# nrf54lv10a_enga_application register map
Vendor: Nordic Semiconductor; Series: nrf54l; File version: 1
CPU: CM33 r0p4, little endian, MPU, FPU, 3 interrupt priority bits, 270 interrupts, 4 SAU regions
Registers are 32-bit, read-write, reset 0x0 unless marked. A register's access mark holds for its fields unless they carry their own. Offsets are from the block's base; [hi:lo] are bit positions; lines under a group give offsets from that group; {n}, {i} and the like mark numbered series; 'fields as' and 'values as' point back to an identical list.

## GLOBAL_SAADC_NS — Analog to Digital Converter 0
Base 0x400D5000
Same registers: GLOBAL_SAADC_S 0x500D5000
0x00 TASKS_START wo — Start the ADC and prepare the result buffer in RAM
  [0] TASKS_START
    1=Trigger task
0x04 TASKS_SAMPLE wo — Take one ADC sample, if scan is enabled all channels are sampled. This task requires that SAADC has started, i.e. EVENTS_STARTED was set and EVENTS_STOPPED was not.
  [0] TASKS_SAMPLE
    1=Trigger task
0x08 TASKS_STOP wo — Stop the ADC and terminate any on-going conversion
  [0] TASKS_STOP
    1=Trigger task
0x0C TASKS_CALIBRATEOFFSET wo — Starts offset auto-calibration
  [0] TASKS_CALIBRATEOFFSET
    1=Trigger task
0x18 TASKS_STOPDMA wo — Stops DMA transfer sub module
  [0] TASKS_STOPDMA
    1=Trigger task
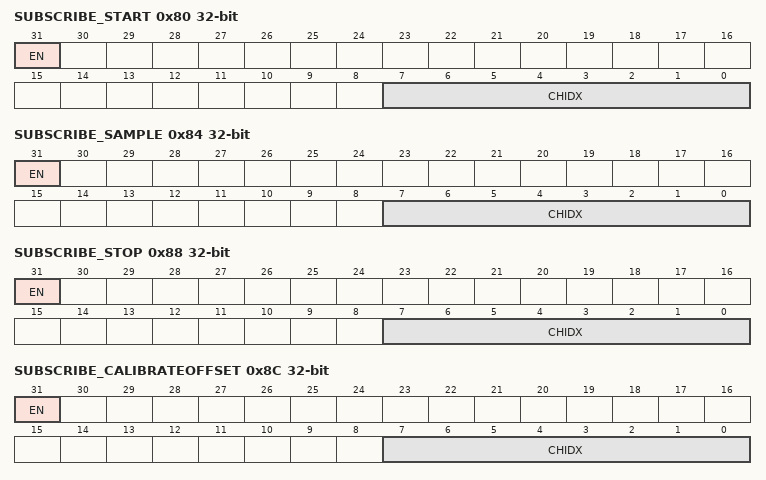
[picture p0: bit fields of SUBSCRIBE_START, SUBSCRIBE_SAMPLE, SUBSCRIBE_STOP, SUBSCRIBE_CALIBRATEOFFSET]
0x80 SUBSCRIBE_START — Subscribe configuration for task START
  [31] EN
    0=Disabled (Disable subscription); 1=Enabled (Enable subscription)
  [7:0] CHIDX — DPPI channel that task START will subscribe to
0x84 SUBSCRIBE_SAMPLE — Subscribe configuration for task SAMPLE
  [31] EN
    values as SUBSCRIBE_START.EN
  [7:0] CHIDX — DPPI channel that task SAMPLE will subscribe to
0x88 SUBSCRIBE_STOP — Subscribe configuration for task STOP
  [31] EN
    values as SUBSCRIBE_START.EN
  [7:0] CHIDX — DPPI channel that task STOP will subscribe to
0x8C SUBSCRIBE_CALIBRATEOFFSET — Subscribe configuration for task CALIBRATEOFFSET
  [31] EN
    values as SUBSCRIBE_START.EN
  [7:0] CHIDX — DPPI channel that task CALIBRATEOFFSET will subscribe to
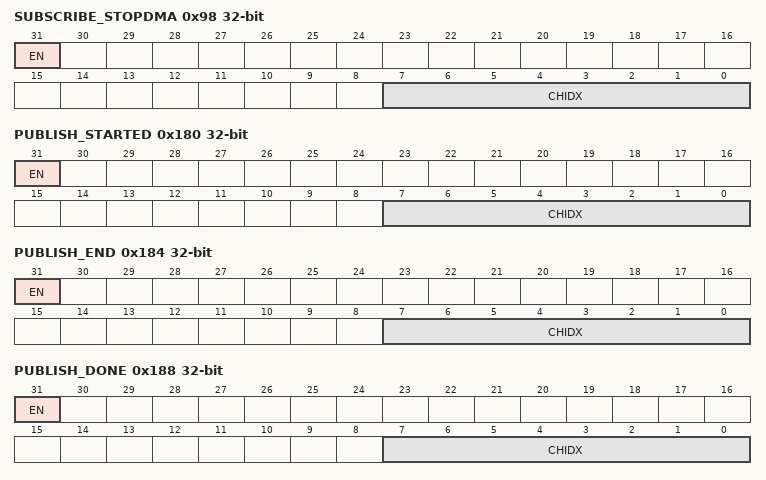
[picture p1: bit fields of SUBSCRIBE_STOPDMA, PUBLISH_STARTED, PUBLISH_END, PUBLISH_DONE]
0x98 SUBSCRIBE_STOPDMA — Subscribe configuration for task STOPDMA
  [31] EN
    values as SUBSCRIBE_START.EN
  [7:0] CHIDX — DPPI channel that task STOPDMA will subscribe to
0x100 EVENTS_STARTED — The ADC has started
  [0] EVENTS_STARTED
    0=NotGenerated (Event not generated); 1=Generated (Event generated)
0x104 EVENTS_END — The ADC has filled up the Result buffer
  [0] EVENTS_END
    values as EVENTS_STARTED.EVENTS_STARTED
0x108 EVENTS_DONE — A conversion task has been completed. Depending on the mode, multiple conversions might be needed for a result to be transferred to RAM.
  [0] EVENTS_DONE
    values as EVENTS_STARTED.EVENTS_STARTED
0x10C EVENTS_RESULTDONE — A result is ready to get transferred to RAM. Result is available in REGRESULT register
  [0] EVENTS_RESULTDONE
    values as EVENTS_STARTED.EVENTS_STARTED
0x110 EVENTS_CALIBRATEDONE — Calibration is complete
  [0] EVENTS_CALIBRATEDONE
    values as EVENTS_STARTED.EVENTS_STARTED
0x114 EVENTS_STOPPED — The ADC has stopped
  [0] EVENTS_STOPPED
    values as EVENTS_STARTED.EVENTS_STARTED
{0x118+8i} EVENTS_CH[{i}] (i=0..7) group — Peripheral events.
  0x00 LIMITH — Description cluster: Last results is equal or above CH[n].LIMIT.HIGH
    [0] LIMITH — Last results is equal or above CH[n].LIMIT.HIGH
      values as EVENTS_STARTED.EVENTS_STARTED
  0x04 LIMITL — Description cluster: Last results is equal or below CH[n].LIMIT.LOW
    [0] LIMITL — Last results is equal or below CH[n].LIMIT.LOW
      values as EVENTS_STARTED.EVENTS_STARTED
0x158 EVENTS_AHBERROR — EasyDMA encountered AHB error.
  [0] EVENTS_AHBERROR
    values as EVENTS_STARTED.EVENTS_STARTED
0x180 PUBLISH_STARTED — Publish configuration for event STARTED
  [31] EN
    0=Disabled (Disable publishing); 1=Enabled (Enable publishing)
  [7:0] CHIDX — DPPI channel that event STARTED will publish to
0x184 PUBLISH_END — Publish configuration for event END
  [31] EN
    values as PUBLISH_STARTED.EN
  [7:0] CHIDX — DPPI channel that event END will publish to
0x188 PUBLISH_DONE — Publish configuration for event DONE
  [31] EN
    values as PUBLISH_STARTED.EN
  [7:0] CHIDX — DPPI channel that event DONE will publish to
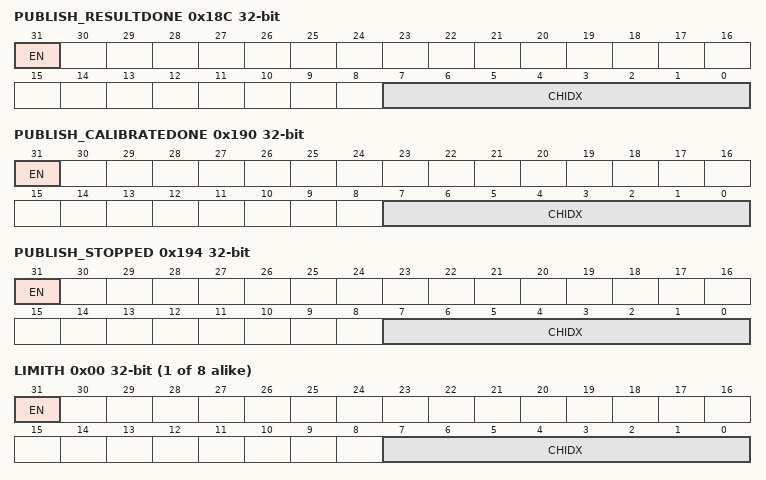
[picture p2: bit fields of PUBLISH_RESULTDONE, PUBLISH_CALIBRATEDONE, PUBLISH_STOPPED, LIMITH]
0x18C PUBLISH_RESULTDONE — Publish configuration for event RESULTDONE
  [31] EN
    values as PUBLISH_STARTED.EN
  [7:0] CHIDX — DPPI channel that event RESULTDONE will publish to
0x190 PUBLISH_CALIBRATEDONE — Publish configuration for event CALIBRATEDONE
  [31] EN
    values as PUBLISH_STARTED.EN
  [7:0] CHIDX — DPPI channel that event CALIBRATEDONE will publish to
0x194 PUBLISH_STOPPED — Publish configuration for event STOPPED
  [31] EN
    values as PUBLISH_STARTED.EN
  [7:0] CHIDX — DPPI channel that event STOPPED will publish to
{0x198+8i} PUBLISH_CH[{i}] (i=0..7) group — Publish configuration for events
  0x00 LIMITH — Description cluster: Publish configuration for event CH[n].LIMITH
    [31] EN
      values as PUBLISH_STARTED.EN
    [7:0] CHIDX — DPPI channel that event CH[n].LIMITH will publish to
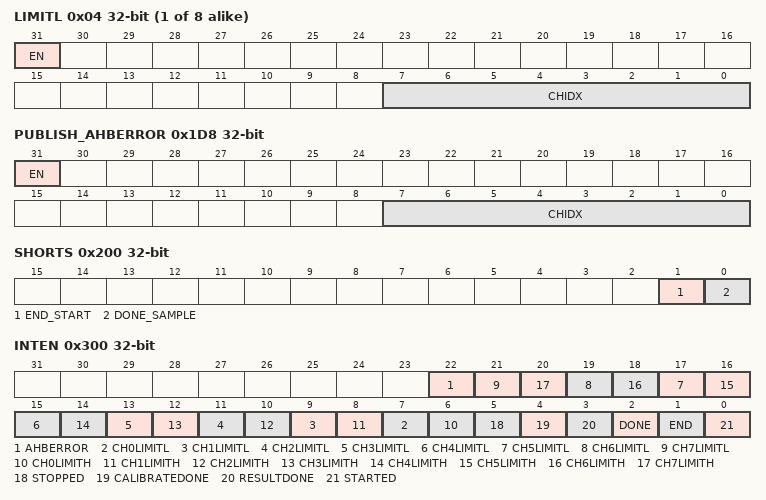
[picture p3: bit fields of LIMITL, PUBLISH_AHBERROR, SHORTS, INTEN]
  0x04 LIMITL — Description cluster: Publish configuration for event CH[n].LIMITL
    [31] EN
      values as PUBLISH_STARTED.EN
    [7:0] CHIDX — DPPI channel that event CH[n].LIMITL will publish to
0x1D8 PUBLISH_AHBERROR — Publish configuration for event AHBERROR
  [31] EN
    values as PUBLISH_STARTED.EN
  [7:0] CHIDX — DPPI channel that event AHBERROR will publish to
0x200 SHORTS — Shortcuts between local events and tasks
  [1] END_START — Shortcut between event END and task START
    0=Disabled (Disable shortcut); 1=Enabled (Enable shortcut)
  [0] DONE_SAMPLE — Shortcut between event DONE and task SAMPLE
    0=Disabled (Disable shortcut); 1=Enabled (Enable shortcut)
0x300 INTEN — Enable or disable interrupt
  [all] fields
    0=Disabled; 1=Enabled
  [22] AHBERROR — Enable or disable interrupt for event AHBERROR
  [2n+7] CH{n}LIMITL (n=0..7) — Enable or disable interrupt for event CH{n}LIMITL
  [2n+6] CH{n}LIMITH (n=0..7) — Enable or disable interrupt for event CH{n}LIMITH
  [5] STOPPED — Enable or disable interrupt for event STOPPED
  [4] CALIBRATEDONE — Enable or disable interrupt for event CALIBRATEDONE
  [3] RESULTDONE — Enable or disable interrupt for event RESULTDONE
  [2] DONE — Enable or disable interrupt for event DONE
  [1] END — Enable or disable interrupt for event END
  [0] STARTED — Enable or disable interrupt for event STARTED
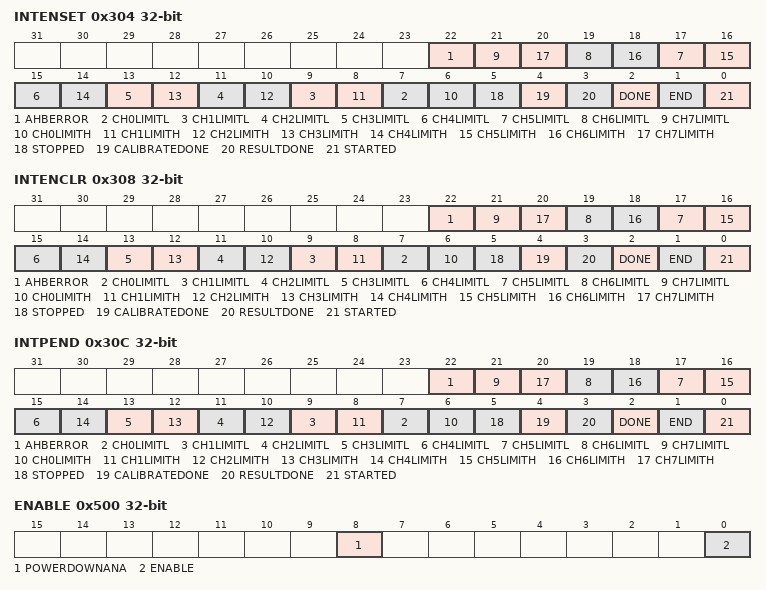
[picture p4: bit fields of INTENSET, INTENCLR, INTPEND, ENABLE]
0x304 INTENSET — Enable interrupt
  [all] fields
    on read: 0=Disabled (Read: Disabled); 1=Enabled (Read: Enabled) | on write: 1=Set (Enable)
  [22] AHBERROR — Write '1' to enable interrupt for event AHBERROR
  [2n+7] CH{n}LIMITL (n=0..7) — Write '1' to enable interrupt for event CH{n}LIMITL
  [2n+6] CH{n}LIMITH (n=0..7) — Write '1' to enable interrupt for event CH{n}LIMITH
  [5] STOPPED — Write '1' to enable interrupt for event STOPPED
  [4] CALIBRATEDONE — Write '1' to enable interrupt for event CALIBRATEDONE
  [3] RESULTDONE — Write '1' to enable interrupt for event RESULTDONE
  [2] DONE — Write '1' to enable interrupt for event DONE
  [1] END — Write '1' to enable interrupt for event END
  [0] STARTED — Write '1' to enable interrupt for event STARTED
0x308 INTENCLR — Disable interrupt
  [all] fields
    on read: 0=Disabled (Read: Disabled); 1=Enabled (Read: Enabled) | on write: 1=Clear (Disable)
  [22] AHBERROR — Write '1' to disable interrupt for event AHBERROR
  [2n+7] CH{n}LIMITL (n=0..7) — Write '1' to disable interrupt for event CH{n}LIMITL
  [2n+6] CH{n}LIMITH (n=0..7) — Write '1' to disable interrupt for event CH{n}LIMITH
  [5] STOPPED — Write '1' to disable interrupt for event STOPPED
  [4] CALIBRATEDONE — Write '1' to disable interrupt for event CALIBRATEDONE
  [3] RESULTDONE — Write '1' to disable interrupt for event RESULTDONE
  [2] DONE — Write '1' to disable interrupt for event DONE
  [1] END — Write '1' to disable interrupt for event END
  [0] STARTED — Write '1' to disable interrupt for event STARTED
0x30C INTPEND ro — Pending interrupts
  [all] fields
    on read: 0=NotPending (Read: Not pending); 1=Pending (Read: Pending)
  [22] AHBERROR — Read pending status of interrupt for event AHBERROR
  [2n+7] CH{n}LIMITL (n=0..7) — Read pending status of interrupt for event CH{n}LIMITL
  [2n+6] CH{n}LIMITH (n=0..7) — Read pending status of interrupt for event CH{n}LIMITH
  [5] STOPPED — Read pending status of interrupt for event STOPPED
  [4] CALIBRATEDONE — Read pending status of interrupt for event CALIBRATEDONE
  [3] RESULTDONE — Read pending status of interrupt for event RESULTDONE
  [2] DONE — Read pending status of interrupt for event DONE
  [1] END — Read pending status of interrupt for event END
  [0] STARTED — Read pending status of interrupt for event STARTED
0x400 STATUS ro
  [0] STATUS
    0=Ready (ADC is ready. No on-going conversion.); 1=Busy (ADC is busy. Single conversion in progress.)
0x404 CLEANPOWERSTATUS ro
  [0] ACK — Ack Status for the clean power request
    0=NoAck (Ack not received.); 1=Ack (Ack received.)
0x408 STATUSANA ro — Status bit for analog macro
  [0] POWERED
    1=Powered (Analog macro is fully powered on); 0=Unpowered (Analog macro is not fully powered on)
0x500 ENABLE — Enable or disable ADC
  [8] POWERDOWNANA — Power down analog between samples. See text for more info.
    0=KeepOn (Keep analog on between samples); 1=PowerDown (Turn off analog between samples)
  [0] ENABLE — Enable or disable ADC
    0=Disabled (Disable ADC); 1=Enabled (Enable ADC)
{0x510+0x10*i} CH[{i}] (i=0..7) group — Unspecified
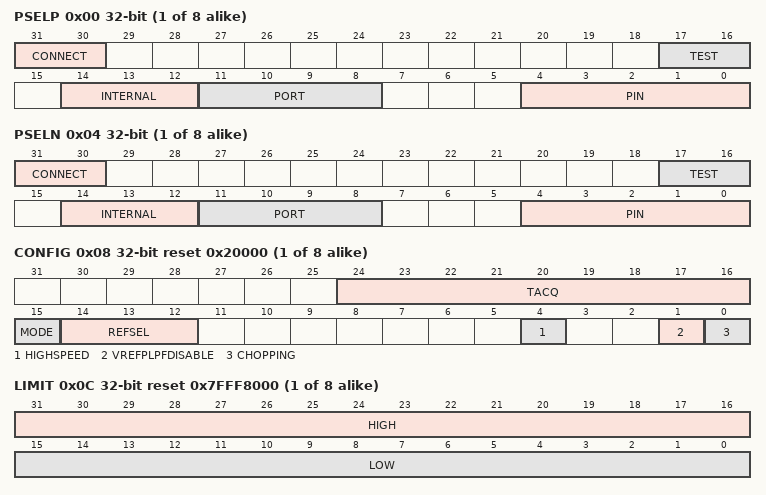
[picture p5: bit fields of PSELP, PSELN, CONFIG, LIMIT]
  0x00 PSELP — Description cluster: Input positive pin selection for CH[n]
    [31:30] CONNECT — Connection
      0=NC (Not connected); 1=AnalogInput (Select analog input); 2=Internal (Selects internal inputs.); 3=Test (Selects test inputs.)
    [17:16] TEST — Test input selection for Analog positive input when CH[n].PSELP.CONNECT = Test
      0=ATB2; 1=ATB1; 2=AVSS; 3=SELREF (Selected reference, voltage determined by PADC_REFSEL)
    [14:12] INTERNAL — Internal input selection for analog positive input when CH[n].PSELP.CONNECT = Internal
      0=Dvdd (Connected to the internal 0.9V digital supply rail); 1=VddL (Connected to VDDL); 2=Vdd (Connected to VDD); 3=VddMeas3V0 (VDD_MEAS_AO_3V0); 4=Vss (Unspecified)
    [11:8] PORT — GPIO port selection
    [4:0] PIN — GPIO pin selection.
  0x04 PSELN — Description cluster: Input negative pin selection for CH[n]
    [31:30] CONNECT — Connection
      values as CH[0].PSELP.CONNECT
    [17:16] TEST — Test input selection for Analog negative input when CH[n].PSELN.CONNECT = Test
      0=ATB0; 1=ATB1; 2=AVSS; 3=SELREF (Selected reference, voltage determined by PADC_REFSEL)
    [14:12] INTERNAL — Internal input selection for Analog negative input when CH[n].PSELN.CONNECT = Internal
      values as CH[0].PSELP.INTERNAL
    [11:8] PORT — GPIO Port selection
    [4:0] PIN — GPIO pin selection.
  0x08 CONFIG reset 0x20000 — Description cluster: Input configuration for CH[n]
    [24:16] TACQ — Acquisition time, the time the ADC uses to sample the input voltage. Resulting acquistion time is ((TACQ+1) x 125 ns)
    [15] MODE — Enable differential mode
      0=SE (Single ended, PSELN will be ignored, negative input to ADC shorted to GND); 1=Differential
    [14:12] REFSEL — Reference control
      0=Internal 1.3 V reference; 1=External reference voltage Reference given at ADC_LP10B_EXT; 2=VddL (Reference given at VDDL VDD_AO_1V5); 3=Vdd (Reference given at VDD VDD_AO_3V0); 4=ExternalNoRefBuf (External reference voltage with reference buffer disabled Reference given at ADC_LP10B_EXT with reference buffer disabled); 5=VddLNoRefBuf (Reference given at VDDL with reference buffer disabled >Reference given at VDD_AO_1V5 with reference buffer disabled)
    [4] HIGHSPEED — Use bootstrapped switches to enable high speed on input
      0=Disabled (High speed is disabled); 1=Enabled (High speed is enabled)
    [1] VREFPLPFDISABLE — Disable internal reference low pass filter
    [0] CHOPPING — Enable chopping
      0=Disabled (Chopping is disabled); 1=Enabled (Chopping is enabled)
  0x0C LIMIT reset 0x7FFF8000 — Description cluster: High/low limits for event monitoring a channel
    [31:16] HIGH — High level limit
    [15:0] LOW — Low level limit
0x5E8 BURST — Enable burst mode
  [0] BURST
    0=Disabled (Burst mode is disabled (normal operation)); 1=Enabled (Burst mode is enabled. SAADC takes 2^OVERSAMPLE number of samples and sends the average to Data RAM.)
0x5EC REGRESULT ro — Last conversion result
  [31:0] REGRESULT — Result of the previous ADC conversion
0x5F0 RESOLUTION reset 0x1 — Resolution configuration
  [2:0] VAL — Set the resolution
    0=8bit; 1=10bit; 2=12bit; 3=14bit; 4=16bit
0x5F4 OVERSAMPLE — Oversampling configuration. OVERSAMPLE should not be combined with SCAN. The RESOLUTION is applied before averaging, thus for high OVERSAMPLE a higher RESOLUTION should be used.
  [3:0] OVERSAMPLE — Oversample control
    0=Bypass oversampling; 1=Over2x (Oversample 2x); 2=Over4x (Oversample 4x); 3=Over8x (Oversample 8x); 4=Over16x (Oversample 16x); 5=Over32x (Oversample 32x); 6=Over64x (Oversample 64x); 7=Over128x (Oversample 128x); 8=Over256x (Oversample 256x); 9=Over512x (Oversample 512x); 10=Over1024x (Oversample 1024x); 11=Over2048x (Oversample 2048x); 12=Over4096x (Oversample 4096x)
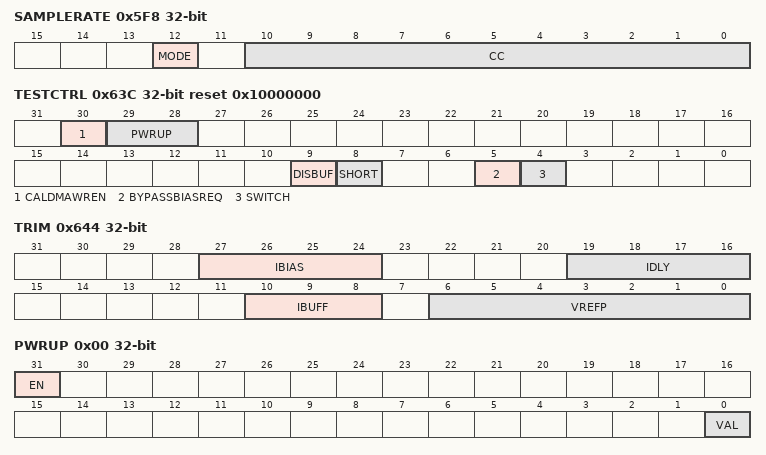
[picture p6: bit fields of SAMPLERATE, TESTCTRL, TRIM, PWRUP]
0x5F8 SAMPLERATE — Controls normal or continuous sample rate
  [12] MODE — Select mode for sample rate control
    0=Task (Rate is controlled from SAMPLE task); 1=Timers (Rate is controlled from local timer (use CC to control the rate))
  [10:0] CC — Capture and compare value. Sample rate is 16 MHz/CC
0x5FC CLEANPOWERREQ — Request for clean power
  [0] REQ — Request
    0=Disabled (Request disabled.); 1=Enabled (Request enabled.)
0x628 RESULT group — RESULT EasyDMA channel
  0x00 DMAENABLE — This register has no other function than defining the value on the dmaChannelPeripheralEnable output. (which is not connected)
    [0] ENABLE — Enable DMA
  0x04 PTR — Data pointer
    [15:0] PTR
  0x08 MAXCNT — Maximum number of buffer bytes to transfer
    [14:0] MAXCNT
  0x0C AMOUNT ro — Number of buffer bytes transferred since last START, updated after the END or STOPPED events
    [14:0] AMOUNT — Number of buffer bytes transferred since last START, updated after the END or STOPPED events.
  0x10 CURRENTAMOUNT ro — Number of buffer bytes transferred since last START, continuously updated
    [14:0] AMOUNT — Number of buffer bytes transferred since last START, continuously updated.
0x63C TESTCTRL reset 0x10000000 — Control signals used during test of ADC
  [30] CALDMAWREN — Enable writing calibration values to DMA
    0=Disabled (Writing values is disabled); 1=Enabled (Writing values is enabled)
  [29:28] PWRUP — Power-up time
    0=6us; 1=10us; 2=15us; 3=20us
  [9] DISBUF — Turn off the VCM buffer inside the SAR-ADC
  [8] SHORT — Short input. Used to measure offset of ADC. See design description for coding
  [5] BYPASSBIASREQ — Bypass bias request, go directly to powerup without waiting for bias current acq
  [4] SWITCH — Swap positive and negative input. See design description for coding
0x640 CAL — Calibration control for offset and gain error
  [6:0] CALOFFSET — Calibration control for offset error. Sign-magnitude coding
    0=Default setting; 31=MaxPos (Maximum positive offset); 32=MaxNeg (maximum negative offset)
0x644 TRIM — Calibration control for reference voltage
  [27:24] IBIAS — Trim bias current for the ADC core. 2s complement
  [19:16] IDLY — Trim bias current for delay cells. 2s complement
  [10:8] IBUFF — To program the current for the VCM buffer insdie ADC core. 2s complement
  [6:0] VREFP — Trim bits to calibrate the internal VREFP to 1.3V
    63=High (Max trim); 0=Default trim; 64=Low (Min trim)
0x658 EASYDMAMODE reset 0x1 — Configure EasyDMA mode.
  [0] LPOP — Enable low-power operation, or use low-latency
    0=Low-latency operation; 1=Low-power operation
0x660 TERMINATEONAHBERROR — Enable EasyDMA termination on AHB error
  [0] ENABLE — Enable termination on AHB error
    0=Disabled (Termination on AHB error disabled); 1=Enabled (Termination on AHB error enabled)
0x664 AHBERRORADDRESS ro — Address of the last AHB error transaction
  [31:0] ADDRESS
0x700 OVERRIDE group — Unspecified
  0x00 PWRUP — Override the PWRUP signal to the analog module
    [31] EN — Enable the override
      0=Disabled (Override is disabled); 1=Enabled (Override is enabled)
    [0] VAL — Override value for the signal
0x800 DFT group — Unspecified
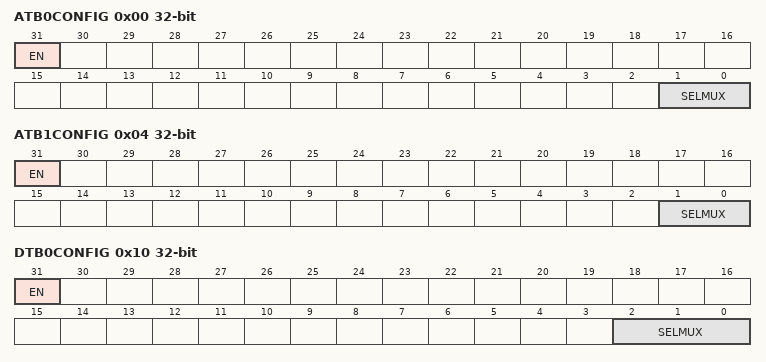
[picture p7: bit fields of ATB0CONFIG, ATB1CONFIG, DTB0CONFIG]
  0x00 ATB0CONFIG — Analog Test Bus 0 (ATB0) configuration
    [31] EN — Enable the analog test bus
      0=Disabled (Analog test bus is disabled); 1=Enabled (Analog test bus is enabled)
    [1:0] SELMUX — Select multiplexer for ATB0
      0=HighImpedance (Unspecified); 1=Dcmux (ATB0 connected to DC input MUX); 2=Bias (ATB0 connected to 1uA bias current)
  0x04 ATB1CONFIG — Analog Test Bus 1 (ATB1) configuration
    [31] EN — Enable the analog test bus
      values as DFT.ATB0CONFIG.EN
    [1:0] SELMUX — Select multiplexer for ATB1
      0=HighImpedance (ATB1 is high impedance); 1=Dcmux (ATB1 connected to DC input MUX); 2=VrefP (ATB1 connected to VREFP)
  0x10 DTB0CONFIG — Digital Test Bus 0 (DTB0) configuration
    [31] EN — Enable the digital test bus
      0=Disabled (Digital test bus is disabled); 1=Enabled (Digital test bus is enabled)
    [2:0] SELMUX — Select multiplexer for DTB0
      {v}=UNKNOWN{v} (v=0..7)
